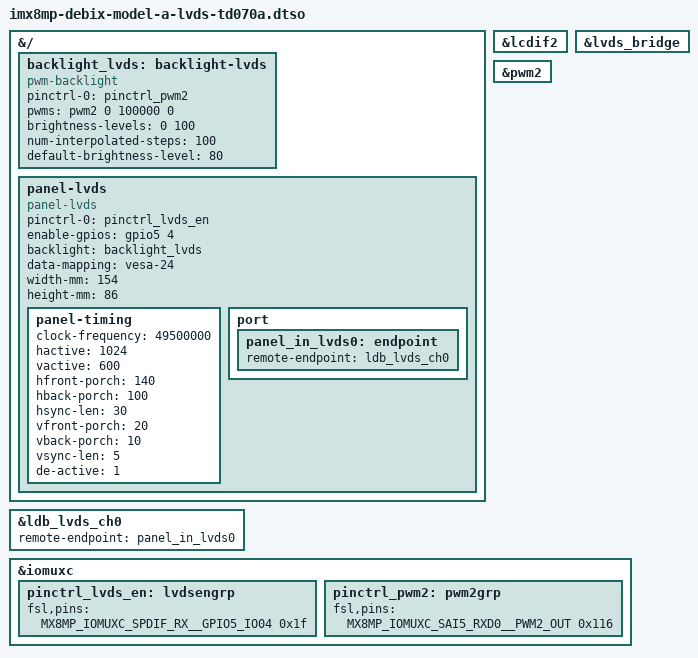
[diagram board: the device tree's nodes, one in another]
// SPDX-License-Identifier: (GPL-2.0+ OR MIT)
/*
 * DEBIX TD070A 7" LVDS panel (JW070R0520B02, 1024x600) on DEBIX Model A.
 * Timing from the vendor panel-simple driver.
 */

/dts-v1/;
/plugin/;

#include <dt-bindings/gpio/gpio.h>
#include "../imx8mp-pinfunc.h"

&{/} {
	backlight_lvds: backlight-lvds {
		compatible = "pwm-backlight";
		pinctrl-names = "default";
		pinctrl-0 = <&pinctrl_pwm2>;
		pwms = <&pwm2 0 100000 0>;
		brightness-levels = <0 100>;
		num-interpolated-steps = <100>;
		default-brightness-level = <80>;
	};

	panel-lvds {
		compatible = "panel-lvds";
		pinctrl-names = "default";
		pinctrl-0 = <&pinctrl_lvds_en>;
		enable-gpios = <&gpio5 4 GPIO_ACTIVE_HIGH>;
		backlight = <&backlight_lvds>;
		data-mapping = "vesa-24";
		width-mm = <154>;
		height-mm = <86>;

		panel-timing {
			clock-frequency = <49500000>;
			hactive = <1024>;
			vactive = <600>;
			hfront-porch = <140>;
			hback-porch = <100>;
			hsync-len = <30>;
			vfront-porch = <20>;
			vback-porch = <10>;
			vsync-len = <5>;
			de-active = <1>;
		};

		port {
			panel_in_lvds0: endpoint {
				remote-endpoint = <&ldb_lvds_ch0>;
			};
		};
	};
};

&lcdif2 {
	status = "okay";
};

&lvds_bridge {
	status = "okay";
};

&ldb_lvds_ch0 {
	remote-endpoint = <&panel_in_lvds0>;
};

&pwm2 {
	status = "okay";
};

&iomuxc {
	pinctrl_lvds_en: lvdsengrp {
		fsl,pins = <
			MX8MP_IOMUXC_SPDIF_RX__GPIO5_IO04		0x1f
		>;
	};

	pinctrl_pwm2: pwm2grp {
		fsl,pins = <
			MX8MP_IOMUXC_SAI5_RXD0__PWM2_OUT		0x116
		>;
	};
};
